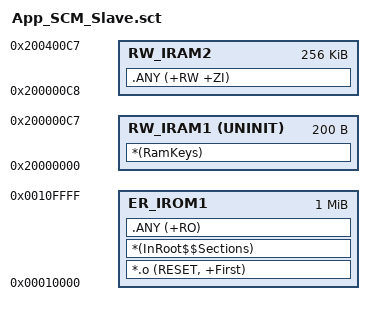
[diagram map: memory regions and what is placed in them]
; *************************************************************
; *** Scatter-Loading Description File generated by uVision ***
; *************************************************************


LR_IROM1 0x00010000 0x00100000  {    ; load region size_region
  ER_IROM1 0x00010000 0x00100000  {  ; load address = execution address
   *.o (RESET, +First)
   *(InRoot$$Sections)
   .ANY (+RO)
  }
   RW_IRAM1 0x20000000 UNINIT 0x000000C8  {  ; No init
    *(RamKeys)
  }
  
   RW_IRAM2 0x200000C8 0x00040000  {  ; RW data
   .ANY (+RW +ZI)
  }
}

